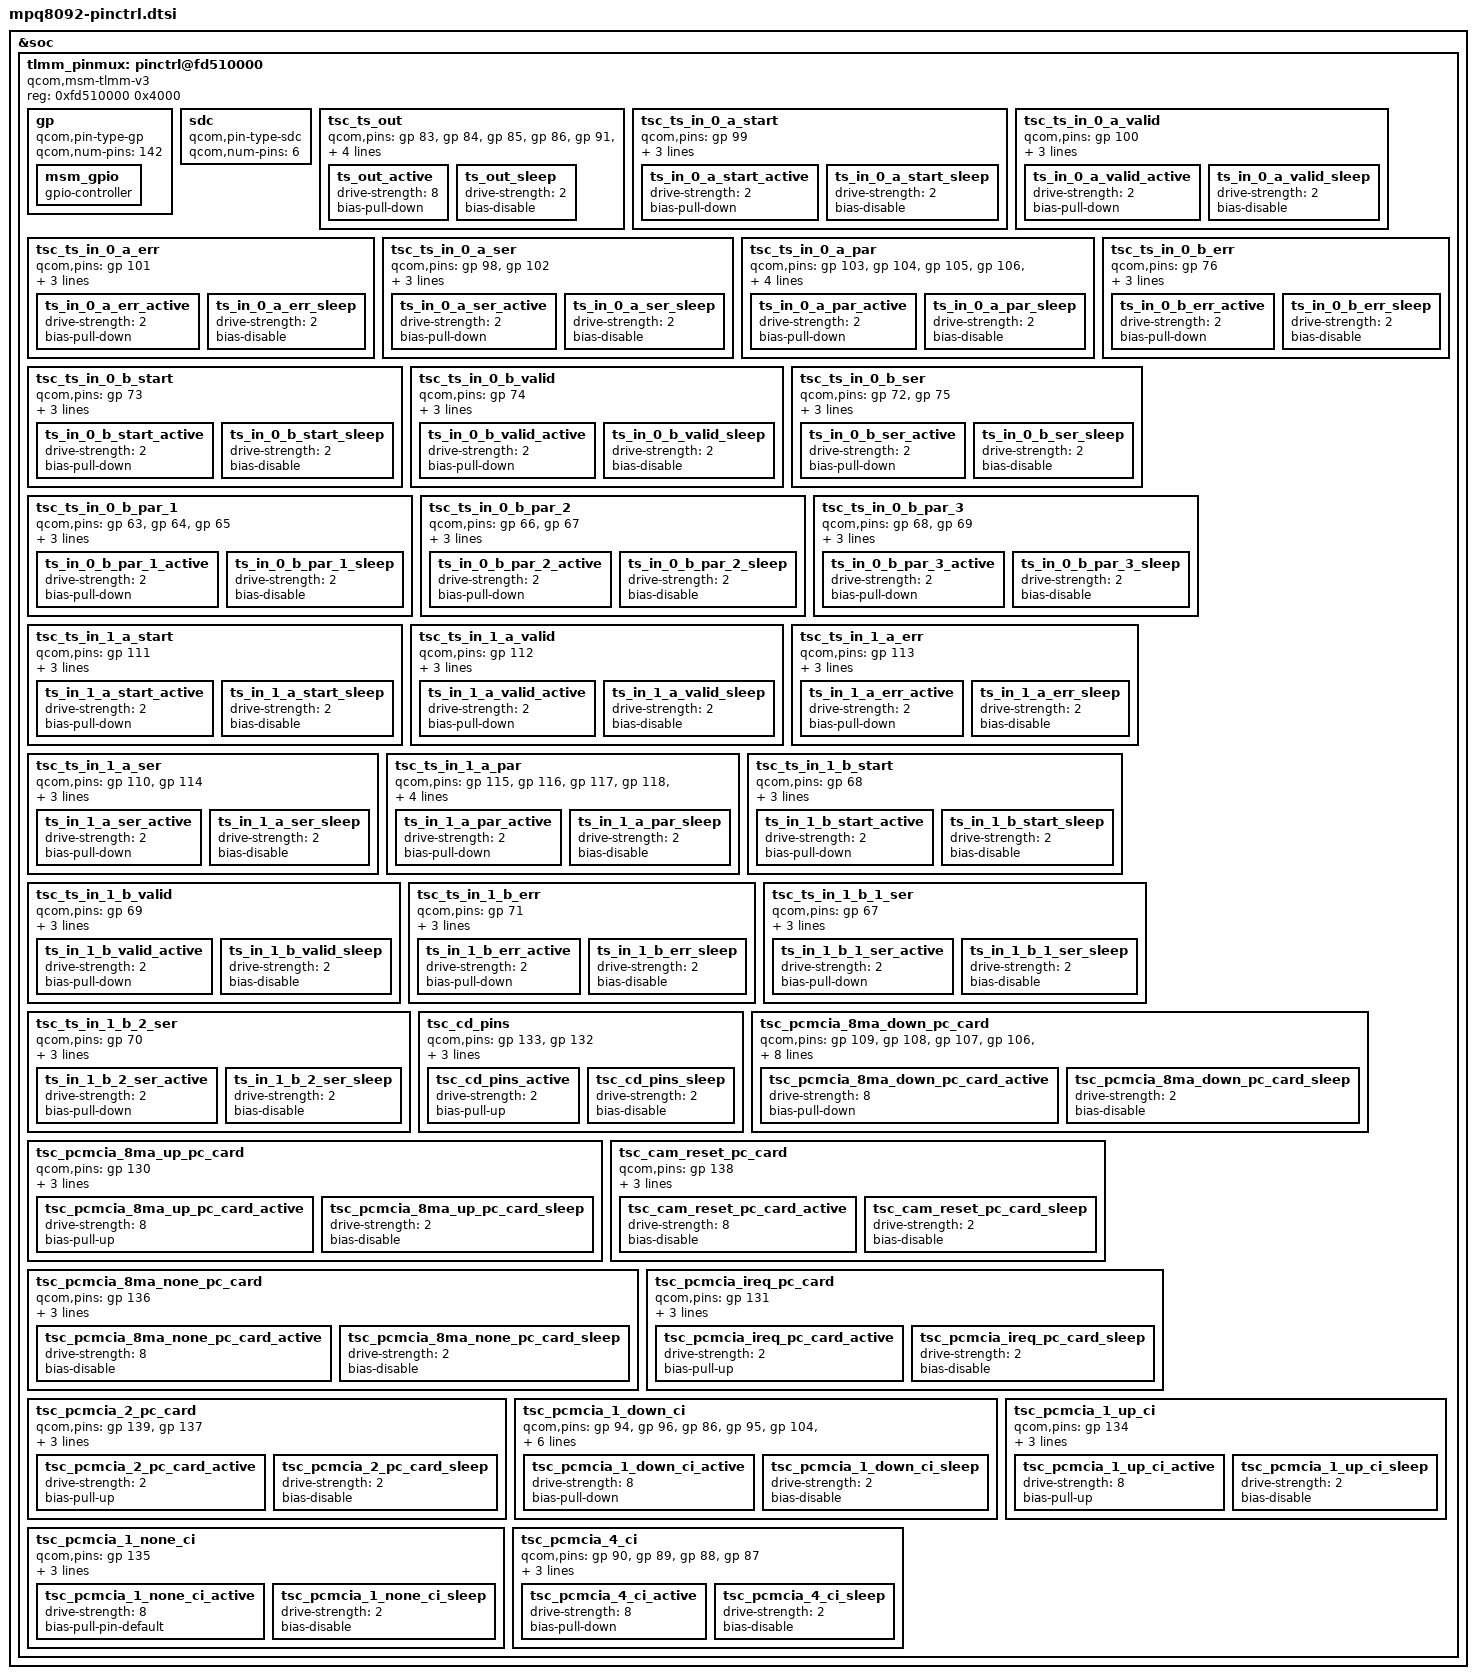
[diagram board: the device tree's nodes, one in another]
/* Copyright (c) 2013, The Linux Foundation. All rights reserved.
 *
 * This program is free software; you can redistribute it and/or modify
 * it under the terms of the GNU General Public License version 2 and
 * only version 2 as published by the Free Software Foundation.
 *
 * This program is distributed in the hope that it will be useful,
 * but WITHOUT ANY WARRANTY; without even the implied warranty of
 * MERCHANTABILITY or FITNESS FOR A PARTICULAR PURPOSE.  See the
 * GNU General Public License for more details.
 */

&soc {
	tlmm_pinmux: pinctrl@fd510000 {
		compatible = "qcom,msm-tlmm-v3";
		reg = <0xfd510000 0x4000>;

		/*General purpose pins*/
		gp: gp {
			qcom,pin-type-gp;
			qcom,num-pins = <142>;
			#qcom,pin-cells = <1>;
			msm_gpio: msm_gpio {
				gpio-controller;
				#gpio-cells = <2>;
			};
		};

		/* SDC pin type */
		sdc: sdc {
			qcom,pin-type-sdc;
			/* 0-2 for sdc1 3-5 for sdc2 */
			qcom,num-pins = <6>;
			/* Order of pins */
			/* CLK -> 0 */
			/* CMD -> 1 */
			/* DATA -> 2 */
			#qcom,pin-cells = <1>;
		};

		/* ts-out */
		tsc_ts_out {
			qcom,pins = <&gp 83>,	/* ts_out_0_valid */
						<&gp 84>,	/* ts_out_0_start */
						<&gp 85>,	/* ts_out_0_clk */
						<&gp 86>,	/* ts_out_0_data[0] */
						<&gp 91>,	/* ts_out_0_data[1] */
						<&gp 92>,	/* ts_out_0_data[2] */
						<&gp 93>,	/* ts_out_0_data[3] */
						<&gp 94>,	/* ts_out_0_data[4] */
						<&gp 95>,	/* ts_out_0_data[5] */
						<&gp 96>,	/* ts_out_0_data[6] */
						<&gp 97>;	/* ts_out_0_data[7] */
			qcom,num-grp-pins = <11>;
			qcom,pin-func = <2>;
			label = "tsc-ts-out";
			ts_out_active: ts_out_active {
				drive-strength = <8>;	/* 8mA */
				bias-pull-down;
			};
			ts_out_sleep: ts_out_sleep {
				drive-strength = <2>;	/* 2mA */
				bias-disable;
			};
		};

		/* TS-in 0 A */
		/* ts-in-0-a-start */
		tsc_ts_in_0_a_start {
			qcom,pins = <&gp 99>;	/* ts_in_0_start_a */
			qcom,num-grp-pins = <1>;
			qcom,pin-func = <2>;
			label = "tsc-ts-in-0-a-start";
			ts_in_0_a_start_active: ts_in_0_a_start_active {
				drive-strength = <2>;	/* 2mA */
				bias-pull-down;
			};
			ts_in_0_a_start_sleep: ts_in_0_a_start_sleep {
				drive-strength = <2>;	/* 2mA */
				bias-disable;
			};
		};

		/* ts-in-0-a-valid */
		tsc_ts_in_0_a_valid {
			qcom,pins = <&gp 100>;	/* ts_in_0_valid_a */
			qcom,num-grp-pins = <1>;
			qcom,pin-func = <2>;
			label = "tsc-ts-in-0-a-valid";
			ts_in_0_a_valid_active: ts_in_0_a_valid_active {
				drive-strength = <2>;	/* 2mA */
				bias-pull-down;
			};
			ts_in_0_a_valid_sleep: ts_in_0_a_valid_sleep {
				drive-strength = <2>;	/* 2mA */
				bias-disable;
			};
		};

		/* ts-in-0-a-err */
		tsc_ts_in_0_a_err {
			qcom,pins = <&gp 101>;	/* ts_in_0_err_a */
			qcom,num-grp-pins = <1>;
			qcom,pin-func = <2>;
			label = "tsc-ts-in-0-a-err";
			ts_in_0_a_err_active: ts_in_0_a_err_active {
				drive-strength = <2>;	/* 2mA */
				bias-pull-down;
			};
			ts_in_0_a_err_sleep: ts_in_0_a_err_sleep {
				drive-strength = <2>;	/* 2mA */
				bias-disable;
			};
		};

		/* ts-in-0-a-serial */
		tsc_ts_in_0_a_ser {
			qcom,pins = <&gp 98>,	/* ts_in_0_clk_a */
						<&gp 102>;	/* ts_in_0_data_a[0] */
			qcom,num-grp-pins = <2>;
			qcom,pin-func = <2>;
			label = "tsc-ts-in-0-a-ser";
			ts_in_0_a_ser_active: ts_in_0_a_ser_active {
				drive-strength = <2>;	/* 2mA */
				bias-pull-down;
			};
			ts_in_0_a_ser_sleep: ts_in_0_a_ser_sleep {
				drive-strength = <2>;	/* 2mA */
				bias-disable;
			};
		};

		/* ts-in-0-a-parallel */
		tsc_ts_in_0_a_par {
			qcom,pins = <&gp 103>,	/* ts_in_0_data_a[1] */
						<&gp 104>,	/* ts_in_0_data_a[2] */
						<&gp 105>,	/* ts_in_0_data_a[3] */
						<&gp 106>,	/* ts_in_0_data_a[4] */
						<&gp 107>,	/* ts_in_0_data_a[5] */
						<&gp 108>,	/* ts_in_0_data_a[6] */
						<&gp 109>;	/* ts_in_0_data_a[7] */
			qcom,num-grp-pins = <7>;
			qcom,pin-func = <2>;
			label = "tsc-ts-in-0-a-par";
			ts_in_0_a_par_active: ts_in_0_a_par_active {
				drive-strength = <2>;	/* 2mA */
				bias-pull-down;
			};
			ts_in_0_a_par_sleep: ts_in_0_a_par_sleep {
				drive-strength = <2>;	/* 2mA */
				bias-disable;
			};
		};

		/* TS-in 0 B */
		/* ts-in-0-b-start */
		tsc_ts_in_0_b_start {
			qcom,pins = <&gp 73>;	/* ts_in_0_start_b */
			qcom,num-grp-pins = <1>;
			qcom,pin-func = <1>;
			label = "tsc-ts-in-0-b-start";
			ts_in_0_b_start_active: ts_in_0_b_start_active {
				drive-strength = <2>;	/* 2mA */
				bias-pull-down;
			};
			ts_in_0_b_start_sleep: ts_in_0_b_start_sleep {
				drive-strength = <2>;	/* 2mA */
				bias-disable;
			};
		};

		/* ts-in-0-b-valid */
		tsc_ts_in_0_b_valid {
			qcom,pins = <&gp 74>;	/* ts_in_0_valid_b */
			qcom,num-grp-pins = <1>;
			qcom,pin-func = <1>;
			label = "tsc-ts-in-0-b-valid";
			ts_in_0_b_valid_active: ts_in_0_b_valid_active {
				drive-strength = <2>;	/* 2mA */
				bias-pull-down;
			};
			ts_in_0_b_valid_sleep: ts_in_0_b_valid_sleep {
				drive-strength = <2>;	/* 2mA */
				bias-disable;
			};
		};

		/* ts-in-0-b-err */
		tsc_ts_in_0_b_err {
			qcom,pins = <&gp 76>;	/* ts_in_0_err_b */
			qcom,num-grp-pins = <1>;
			qcom,pin-func = <1>;
			label = "tsc-ts-in-0-b-err";
			ts_in_0_b_err_active: ts_in_0_b_err_active {
				drive-strength = <2>;	/* 2mA */
				bias-pull-down;
			};
			ts_in_0_b_err_sleep: ts_in_0_b_err_sleep {
				drive-strength = <2>;	/* 2mA */
				bias-disable;
			};
		};

		/* ts-in-0-b-serial */
		tsc_ts_in_0_b_ser {
			qcom,pins = <&gp 72>,	/* ts_in_0_clk_b */
						<&gp 75>;	/* ts_in_0_data_b[0] */
			qcom,num-grp-pins = <2>;
			qcom,pin-func = <1>;
			label = "ts-in-0-b-ser";
			ts_in_0_b_ser_active: ts_in_0_b_ser_active {
				drive-strength = <2>;	/* 2mA */
				bias-pull-down;
			};
			ts_in_0_b_ser_sleep: ts_in_0_b_ser_sleep {
				drive-strength = <2>;	/* 2mA */
				bias-disable;
			};
		};

		/* ts-in-0-b-parallel (classified by func) */
		tsc_ts_in_0_b_par_1 {
			qcom,pins = <&gp 63>,	/* ts_in_0_data_b[1] */
						<&gp 64>,	/* ts_in_0_data_b[2] */
						<&gp 65>;	/* ts_in_0_data_b[3] */
			qcom,num-grp-pins = <3>;
			qcom,pin-func = <1>;
			label = "ts-in-0-b-par1";
			ts_in_0_b_par_1_active: ts_in_0_b_par_1_active {
				drive-strength = <2>;	/* 2mA */
				bias-pull-down;
			};
			ts_in_0_b_par_1_sleep: ts_in_0_b_par_1_sleep {
				drive-strength = <2>;	/* 2mA */
				bias-disable;
			};
		};

		tsc_ts_in_0_b_par_2 {
			qcom,pins = <&gp 66>,	/* ts_in_0_data_b[4] */
						<&gp 67>;	/* ts_in_0_data_b[5] */
			qcom,num-grp-pins = <2>;
			qcom,pin-func = <2>;
			label = "ts-in-0-b-par2";
			ts_in_0_b_par_2_active: ts_in_0_b_par_2_active {
				drive-strength = <2>;	/* 2mA */
				bias-pull-down;
			};
			ts_in_0_b_par_2_sleep: ts_in_0_b_par_2_sleep {
				drive-strength = <2>;	/* 2mA */
				bias-disable;
			};
		};

		tsc_ts_in_0_b_par_3 {
			qcom,pins = <&gp 68>,	/* ts_in_0_data_b[6] */
						<&gp 69>;	/* ts_in_0_data_b[7] */
			qcom,num-grp-pins = <2>;
			qcom,pin-func = <3>;
			label = "ts-in-0-b-par3";
			ts_in_0_b_par_3_active: ts_in_0_b_par_3_active {
				drive-strength = <2>;	/* 2mA */
				bias-pull-down;
			};
			ts_in_0_b_par_3_sleep: ts_in_0_b_par_3_sleep {
				drive-strength = <2>;	/* 2mA */
				bias-disable;
			};
		};

		/* TS-in 1 A */
		/* ts-in-1-a-start */
		tsc_ts_in_1_a_start {
			qcom,pins = <&gp 111>;	/* ts_in_1_start_a */
			qcom,num-grp-pins = <1>;
			qcom,pin-func = <2>;
			label = "tsc-ts-in-1-a-start";
			ts_in_1_a_start_active: ts_in_1_a_start_active {
				drive-strength = <2>;	/* 2mA */
				bias-pull-down;
			};
			ts_in_1_a_start_sleep: ts_in_1_a_start_sleep {
				drive-strength = <2>;	/* 2mA */
				bias-disable;
			};
		};

		/* ts-in-1-a-valid */
		tsc_ts_in_1_a_valid {
			qcom,pins = <&gp 112>;	/* ts_in_1_valid_a */
			qcom,num-grp-pins = <1>;
			qcom,pin-func = <2>;
			label = "tsc-ts-in-1-a-valid";
			ts_in_1_a_valid_active: ts_in_1_a_valid_active {
				drive-strength = <2>;	/* 2mA */
				bias-pull-down;
			};
			ts_in_1_a_valid_sleep: ts_in_1_a_valid_sleep {
				drive-strength = <2>;	/* 2mA */
				bias-disable;
			};
		};

		/* ts-in-1-a-err */
		tsc_ts_in_1_a_err {
			qcom,pins = <&gp 113>;	/* ts_in_1_err_a */
			qcom,num-grp-pins = <1>;
			qcom,pin-func = <2>;
			label = "tsc-ts-in-1-a-err";
			ts_in_1_a_err_active: ts_in_1_a_err_active {
				drive-strength = <2>;	/* 2mA */
				bias-pull-down;
			};
			ts_in_1_a_err_sleep: ts_in_1_a_err_sleep {
				drive-strength = <2>;	/* 2mA */
				bias-disable;
			};
		};

		/* ts-in-1-a-serial */
		tsc_ts_in_1_a_ser {
			qcom,pins = <&gp 110>,	/* ts_in_1_clk_a */
						<&gp 114>;	/* ts_in_1_data0_a */
			qcom,num-grp-pins = <2>;
			qcom,pin-func = <2>;
			label = "tsc-ts-in-1-a-ser";
			ts_in_1_a_ser_active: ts_in_1_a_ser_active {
				drive-strength = <2>;	/* 2mA */
				bias-pull-down;
			};
			ts_in_1_a_ser_sleep: ts_in_1_a_ser_sleep {
				drive-strength = <2>;	/* 2mA */
				bias-disable;
			};
		};

		/* ts-in-1-a-parallel */
		tsc_ts_in_1_a_par {
			qcom,pins = <&gp 115>,	/* ts_in_1_data[1] */
						<&gp 116>,	/* ts_in_1_data[2] */
						<&gp 117>,	/* ts_in_1_data[3] */
						<&gp 118>,	/* ts_in_1_data[4] */
						<&gp 119>,	/* ts_in_1_data[5] */
						<&gp 120>,	/* ts_in_1_data[6] */
						<&gp 121>;	/* ts_in_1_data[7] */
			qcom,num-grp-pins = <7>;
			qcom,pin-func = <2>;
			label = "tsc-ts-in-1-par";
			ts_in_1_a_par_active: ts_in_1_a_par_active {
				drive-strength = <2>;	/* 2mA */
				bias-pull-down;
			};
			ts_in_1_a_par_sleep: ts_in_1_a_par_sleep {
				drive-strength = <2>;	/* 2mA */
				bias-disable;
			};
		};

		/* TS-in 1 B */
		/* ts-in-1-b-start */
		tsc_ts_in_1_b_start {
			qcom,pins = <&gp 68>;	/* ts_in_1_start_b */
			qcom,num-grp-pins = <1>;
			qcom,pin-func = <2>;
			label = "tsc-ts-in-1-b-start";
			ts_in_1_b_start_active: ts_in_1_b_start_active {
				drive-strength = <2>;	/* 2mA */
				bias-pull-down;
			};
			ts_in_1_b_start_sleep: ts_in_1_b_start_sleep {
				drive-strength = <2>;	/* 2mA */
				bias-disable;
			};
		};

		/* ts-in-1-b-valid */
		tsc_ts_in_1_b_valid {
			qcom,pins = <&gp 69>;	/* ts_in_1_valid_b */
			qcom,num-grp-pins = <1>;
			qcom,pin-func = <2>;
			label = "tsc-ts-in-1-b-valid";
			ts_in_1_b_valid_active: ts_in_1_b_valid_active {
				drive-strength = <2>;	/* 2mA */
				bias-pull-down;
			};
			ts_in_1_b_valid_sleep: ts_in_1_b_valid_sleep {
				drive-strength = <2>;	/* 2mA */
				bias-disable;
			};
		};

		/* ts-in-1-b-err */
		tsc_ts_in_1_b_err {
			qcom,pins = <&gp 71>;	/* ts_in_1_err_b */
			qcom,num-grp-pins = <1>;
			qcom,pin-func = <1>;
			label = "tsc-ts-in-1-b-err";
			ts_in_1_b_err_active: ts_in_1_b_err_active {
				drive-strength = <2>;	/* 2mA */
				bias-pull-down;
			};
			ts_in_1_b_err_sleep: ts_in_1_b_err_sleep {
				drive-strength = <2>;	/* 2mA */
				bias-disable;
			};
		};

		/* ts-in-1-b-serial (classified by func) */
		tsc_ts_in_1_b_1_ser {
			qcom,pins = <&gp 67>;	/* ts_in_1_clk_b */
			qcom,num-grp-pins = <1>;
			qcom,pin-func = <1>;
			label = "tsc-ts-in-1-b-ser1";
			ts_in_1_b_1_ser_active: ts_in_1_b_1_ser_active {
				drive-strength = <2>;	/* 2mA */
				bias-pull-down;
			};
			ts_in_1_b_1_ser_sleep: ts_in_1_b_1_ser_sleep {
				drive-strength = <2>;	/* 2mA */
				bias-disable;
			};
		};

		tsc_ts_in_1_b_2_ser {
			qcom,pins = <&gp 70>;	/* ts_in_1_data0_b */
			qcom,num-grp-pins = <1>;
			qcom,pin-func = <2>;
			label = "tsc-ts-in-1-b-ser2";
			ts_in_1_b_2_ser_active: ts_in_1_b_2_ser_active {
				drive-strength = <2>;	/* 2mA */
				bias-pull-down;
			};
			ts_in_1_b_2_ser_sleep: ts_in_1_b_2_ser_sleep {
				drive-strength = <2>;	/* 2mA */
				bias-disable;
			};
		};

		/* CAM card detection pins */
		tsc_cd_pins {
			qcom,pins = <&gp 133>, /* pcmcia_ci_cd_n_0 No.36 in the CI spec */
						<&gp 132>; /* pcmcia_ci_cd_n_1 No.67 in the CI spec */
			qcom,num-grp-pins = <2>;
			qcom,pin-func = <1>;
			label = "tsc-cd-pins";
			tsc_cd_pins_active: tsc_cd_pins_active {
				drive-strength = <2>;
				bias-pull-up;
			};
			tsc_cd_pins_sleep: tsc_cd_pins_sleep {  /* TODO: is the sleep state needed? */
				drive-strength = <2>;	/* 2mA */
				bias-disable;
			};
		};

		/* pcmcia pins enabled at card insertion (classified by drvstr and pull mode)*/
		tsc_pcmcia_8ma_down_pc_card {
			qcom,pins = <&gp 109>,	/* pcmcia_d[3] No.2 in the CI spec */
						<&gp 108>,	/* pcmcia_d[4] No.3 in the CI spec */
						<&gp 107>, /* pcmcia_d[5] No.4 in the CI spec */
						<&gp 106>, /* pcmcia_d[6] No.5 in the CI spec */
						<&gp 105>, /* pcmcia_d[7] No.6 in the CI spec */
						<&gp 128>, /* pcmcia_cen_0 No.7 in the CI spec */
						<&gp 117>, /* pcmcia_a[10] No.8 in the CI spec */
						<&gp 116>, /* pcmcia_a[11] No.10 in the CI spec */
						<&gp 118>, /* pcmcia_a[9] No.11 in the CI spec */
						<&gp 119>, /* pcmcia_a[8] No.12 in the CI spec */
						<&gp 114>, /* pcmcia_a[13] No.13 in the CI spec */
						<&gp 113>, /* pcmcia_a[14] No.14 in the CI spec */
						<&gp 129>, /* pcmcia_wen No.15 in the CI spec */
						<&gp 115>, /* pcmcia_a[12] No.21 in the CI spec */
						<&gp 120>, /* pcmcia_a[7] No.22 in the CI spec */
						<&gp 121>, /* pcmcia_a[6] No.23 in the CI spec */
						<&gp 122>, /* pcmcia_a[5] No.24 in the CI spec */
						<&gp 123>, /* pcmcia_a[4] No.25 in the CI spec */
						<&gp 124>, /* pcmcia_a[3] No.26 in the CI spec */
						<&gp 125>, /* pcmcia_a[2] No.27 in the CI spec */
						<&gp 126>, /* pcmcia_a[1] No.28 in the CI spec */
						<&gp 127>, /* pcmcia_a[0] No.29 in the CI spec */
						<&gp 112>, /* pcmcia_d[0] No.30 in the CI spec */
						<&gp 111>, /* pcmcia_d[1] No.31 in the CI spec */
						<&gp 110>; /* pcmcia_d[2] No.32 in the CI spec */
			qcom,num-grp-pins = <25>;
			qcom,pin-func = <1>;
			label = "tsc-pcmcia-8ma_down-pc-card";
			tsc_pcmcia_8ma_down_pc_card_active: tsc_pcmcia_8ma_down_pc_card_active {
				drive-strength = <8>;	/* 8mA */
				bias-pull-down;
			};
			tsc_pcmcia_8ma_down_pc_card_sleep: tsc_pcmcia_8ma_down_pc_card_sleep {
				drive-strength = <2>;	/* 2mA */
				bias-disable;
			};
		};

		tsc_pcmcia_8ma_up_pc_card {
			qcom,pins = <&gp 130>; /* pcmcia_oen No.9 in the CI spec */
			qcom,num-grp-pins = <1>;
			qcom,pin-func = <1>;
			label = "tsc-pcmcia-8ma-up-pc-card";
			tsc_pcmcia_8ma_up_pc_card_active: tsc_pcmcia_8ma_up_pc_card_active {
				drive-strength = <8>;	/* 8mA */
				bias-pull-up;
			};
			tsc_pcmcia_8ma_up_pc_card_sleep: tsc_pcmcia_8ma_up_pc_card_sleep {
				drive-strength = <2>;	/* 2mA */
				bias-disable;
			};
		};

		tsc_cam_reset_pc_card {
			qcom,pins = <&gp 138>; /* pcmcia_rst No.58 in the CI spec */
			qcom,num-grp-pins = <1>;
			label = "tsc-cam-reset-pc-card";
			qcom,pin-func = <0>;
			tsc_cam_reset_pc_card_active: tsc_cam_reset_pc_card_active {
				drive-strength = <8>;	/* 8mA */
				bias-disable;
			};
			tsc_cam_reset_pc_card_sleep: tsc_cam_reset_pc_card_sleep {
				drive-strength = <2>;	/* 2mA */
				bias-disable;
			};
		};

		tsc_pcmcia_8ma_none_pc_card {
			qcom,pins = <&gp 136>; /* pcmcia_reg_n No.61 in the CI spec */
			qcom,num-grp-pins = <1>;
			qcom,pin-func = <1>;
			label = "tsc-pcmcia-8ma-none-pc-card";
			tsc_pcmcia_8ma_none_pc_card_active: tsc_pcmcia_8ma_none_pc_card_active {
				drive-strength = <8>;	/* 8mA */
				bias-disable;
			};
			tsc_pcmcia_8ma_none_pc_card_sleep: tsc_pcmcia_8ma_none_pc_card_sleep {
				drive-strength = <2>;	/* 2mA */
				bias-disable;
			};
		};

		tsc_pcmcia_ireq_pc_card {
			qcom,pins = <&gp 131>; /* IREQ# No.16 in the CI spec */
			qcom,num-grp-pins = <1>;
			qcom,pin-func = <1>; /* TODO: should this be gpio? */
			label = "tsc-pcmcia-ireq-pc-card";
			tsc_pcmcia_ireq_pc_card_active: tsc_pcmcia_ireq_pc_card_active {
				drive-strength = <2>;	/* 2mA */
				bias-pull-up;
			};
			tsc_pcmcia_ireq_pc_card_sleep: tsc_pcmcia_ireq_pc_card_sleep {
				drive-strength = <2>;	/* 2mA */
				bias-disable;
			};
		};
		tsc_pcmcia_2_pc_card {
			qcom,pins = <&gp 139>, /* pcmcia_wait_n No.59 in the CI spec */
						<&gp 137>; /* pcmcia_inpack_n No.60 in the CI spec */
			qcom,num-grp-pins = <2>;
			qcom,pin-func = <1>;
			label = "tsc-pcmcia-2-pc-card";
			tsc_pcmcia_2_pc_card_active: tsc_pcmcia_2_pc_card_active {
				drive-strength = <2>;	/* 2mA */
				bias-pull-up;
			};
			tsc_pcmcia_2_pc_card_sleep: tsc_pcmcia_2_pc_card_sleep {
				drive-strength = <2>;	/* 2mA */
				bias-disable;
			};
		};

		/* pcmcia pins enabled at personality change to CI/+ (classified by
		 * function and pull mode) */
		tsc_pcmcia_1_down_ci {
			qcom,pins = <&gp 94>, /* pcmcia_mival No.19 in the CI spec */
						<&gp 96>, /* pcmcia_mclki No.20 in the CI spec */
						<&gp 86>, /* pcmcia_mdo[7] No.41 in the CI spec */
						<&gp 95>, /* pcmcia_mistr No.46 in the CI spec */
						<&gp 104>, /* pcmcia_mdi[0] No.47 in the CI spec */
						<&gp 103>, /* pcmcia_mdi[1] No.48 in the CI spec */
						<&gp 102>, /* pcmcia_mdi[2] No.49 in the CI spec */
						<&gp 101>, /* pcmcia_mdi[3] No.50 in the CI spec */
						<&gp 100>, /* pcmcia_mdi[4] No.53 in the CI spec */
						<&gp 99>, /* pcmcia_mdi[5] No.54 in the CI spec */
						<&gp 98>, /* pcmcia_mdi[6] No.55 in the CI spec */
						<&gp 97>, /* pcmcia_mdi[7] No.56 in the CI spec */
						<&gp 83>, /* pcmcia_moval No.62 in the CI spec */
						<&gp 84>, /* pcmcia_mostr No.63 in the CI spec */
						<&gp 93>, /* pcmcia_mdo[0] No.64 in the CI spec */
						<&gp 92>, /* pcmcia_mdo[1] No.65 in the CI spec */
						<&gp 91>; /* pcmcia_mdo[2] No.66 in the CI spec */
			qcom,num-grp-pins = <17>;
			qcom,pin-func = <1>;
			label = "tsc-pcmcia-1-down-ci";
			tsc_pcmcia_1_down_ci_active: tsc_pcmcia_1_down_ci_active {
				drive-strength = <8>;	/* 8mA */
				bias-pull-down;
			};
			tsc_pcmcia_1_down_ci_sleep: tsc_pcmcia_1_down_ci_sleep {
				drive-strength = <2>;	/* 2mA */
				bias-disable;
			};
		};

		tsc_pcmcia_1_up_ci {
			qcom,pins = <&gp 134>; /* pcmcia_iord_n No.44 in the CI spec */
			qcom,num-grp-pins = <1>;
			qcom,pin-func = <1>;
			label = "tsc-pcmcia-1-up-ci";
			tsc_pcmcia_1_up_ci_active: tsc_pcmcia_1_up_ci_active {
				drive-strength = <8>;	/* 8mA */
				bias-pull-up;
			};
			tsc_pcmcia_1_up_ci_sleep: tsc_pcmcia_1_up_ci_sleep {
				drive-strength = <2>;	/* 2mA */
				bias-disable;
			};
		};

		tsc_pcmcia_1_none_ci {
			qcom,pins = <&gp 135>; /* pcmcia_iowr_n No.45 in the CI spec */
			qcom,num-grp-pins = <1>;
			qcom,pin-func = <1>;
			label = "tsc-pcmcia-1-none-ci";
			tsc_pcmcia_1_none_ci_active: tsc_pcmcia_1_none_ci_active {
				drive-strength = <8>;	/* 8mA */
				bias-pull-pin-default; /* TODO: should this be when none? */
			};
			tsc_pcmcia_1_none_ci_sleep: tsc_pcmcia_1_none_ci_sleep {
				drive-strength = <2>;	/* 2mA */
				bias-disable;
			};
		};

		tsc_pcmcia_4_ci{
			qcom,pins = <&gp 90>, /* pcmcia_mdo[3] No.37 in the CI spec */
						<&gp 89>, /* pcmcia_mdo[4] No.38 in the CI spec */
						<&gp 88>, /* pcmcia_mdo[5] No.39 in the CI spec */
						<&gp 87>; /* pcmcia_mdo[6] No.40 in the CI spec */
			qcom,num-grp-pins = <4>;
			qcom,pin-func = <4>;
			label = "tsc-pcmcia-4-ci";
			tsc_pcmcia_4_ci_active: tsc_pcmcia_4_ci_active {
				drive-strength = <8>;	/* 8mA */
				bias-pull-down;
			};
			tsc_pcmcia_4_ci_sleep: tsc_pcmcia_4_ci_sleep {
				drive-strength = <2>;	/* 2mA */
				bias-disable;
			};
		};
	};
};
